VERSION ""

NS_ :

BS_:

BU_:

BO_ 2147487744 buttons: 1 Vector__XXX
 SG_ encoder : 6|1@0+ (1,0) [0|0] "" Vector__XXX
 SG_ shift : 7|1@0+ (1,0) [0|1] "" Vector__XXX

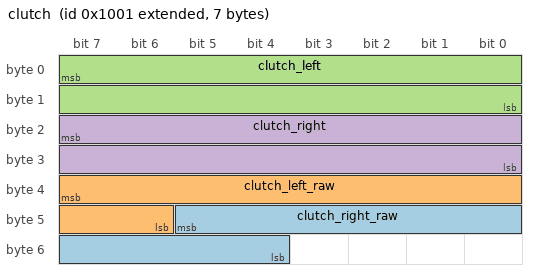
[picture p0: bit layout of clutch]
BO_ 2147487745 clutch: 7 Vector__XXX
 SG_ clutch_right_raw : 45|10@0+ (1,0) [0|0] "" Vector__XXX
 SG_ clutch_left_raw : 39|10@0+ (1,0) [0|0] "" Vector__XXX
 SG_ clutch_left : 7|16@0+ (0.01,0) [0|100] "%" Vector__XXX
 SG_ clutch_right : 23|16@0+ (0.01,0) [0|100] "%" Vector__XXX

BA_DEF_  "BusType" STRING ;
BA_DEF_ BO_  "GenMsgCycleTime" INT 0 0;
BA_DEF_DEF_  "BusType" "CAN";
BA_DEF_DEF_  "GenMsgCycleTime" 0;
BA_ "GenMsgCycleTime" BO_ 2147487745 10;
VAL_ 2147487744 encoder 2 "PRESSED" 0 "CLOCKWISE" 1 "COUNTER_CLOCKWISE" ;
VAL_ 2147487744 shift 1 "DOWN" 0 "UP" ;
